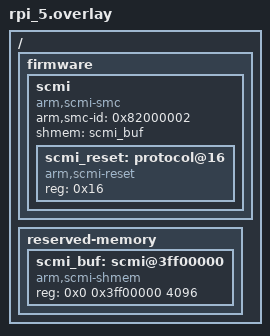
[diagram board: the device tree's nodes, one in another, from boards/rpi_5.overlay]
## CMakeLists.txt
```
# Copyright 2024 EPAM Systems
#
# SPDX-License-Identifier: Apache-2.0

cmake_minimum_required(VERSION 3.20.0)
find_package(Zephyr REQUIRED HINTS $ENV{ZEPHYR_BASE})
project(arm_scmi_shell)

target_sources(app PRIVATE
	src/main.c
	src/shell.c
)

target_sources_ifdef(CONFIG_ARM_SCMI_RESET_HELPERS app PRIVATE
	src/shell_reset.c
)
```

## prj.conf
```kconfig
# Copyright 2024 EPAM Systems
# SPDX-License-Identifier: Apache-2.0

CONFIG_LOG=y
CONFIG_LOG_MODE_MINIMAL=y
CONFIG_PRINTK=y
CONFIG_SHELL=y

CONFIG_ARM_SCMI=y
CONFIG_ARM_SCMI_BASE_EXT_REV=y
```

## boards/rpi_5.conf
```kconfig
# Copyright (c) 2024 EPAM Systems
# SPDX-License-Identifier: Apache-2.0

CONFIG_ARM_SCMI_BASE_AGENT_HELPERS=y
CONFIG_RESET=y
```

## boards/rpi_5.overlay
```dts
/*
 * Copyright (c) 2024 EPAM Systems
 *
 * SPDX-License-Identifier: Apache-2.0
 */

/ {
	firmware {
		scmi {
			compatible = "arm,scmi-smc";
			arm,smc-id = <0x82000002>;
			#address-cells = <1>;
			#size-cells = <0>;
			shmem = <&scmi_buf>;

			scmi_reset: protocol@16 {
				compatible = "arm,scmi-reset";
				reg = <0x16>;
				#reset-cells = <1>;
			};
		};
	};

	reserved-memory {
		#address-cells = <2>;
		#size-cells = <1>;
		ranges;

		scmi_buf: scmi@3ff00000 {
			compatible = "arm,scmi-shmem";
			reg = <0x0 0x3ff00000 4096>;
		};
	};
};
```

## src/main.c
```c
/*
 * Copyright (c) 2024 EPAM Systems
 *
 * SPDX-License-Identifier: Apache-2.0
 *
 * A sample application for demonstrating ARM SCMI Platform interface access using shell commands.
 */

#include <zephyr/kernel.h>

int main(void)
{
	printk("ARM SCMI shell sample\n");
}
```

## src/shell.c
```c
/*
 * System Control and Management Interface (SCMI) Shell interface
 *
 * Copyright (c) 2024 EPAM Systems
 *
 * SPDX-License-Identifier: Apache-2.0
 */

#include <zephyr/kernel.h>
#include <zephyr/drivers/firmware/scmi/protocol.h>
#include <zephyr/drivers/firmware/scmi/base.h>
#include <zephyr/shell/shell.h>

static int scmi_shell_base_revision(const struct shell *sh, size_t argc, char **argv)
{
	struct scmi_revision_info rev;
	int ret;

	ret = scmi_base_get_revision_info(&rev);
	if (ret) {
		shell_error(sh, "base proto get revision failed (%d)", ret);
		return ret;
	}

	shell_print(sh, "ARM SCMI base protocol v%04x.%04x", rev.major_ver, rev.minor_ver);

#if defined(CONFIG_ARM_SCMI_BASE_EXT_REV)
	shell_print(sh, "  vendor\t:%s", rev.vendor_id);
	shell_print(sh, "  subvendor\t:%s", rev.sub_vendor_id);
	shell_print(sh, "  fw version\t:0x%x", rev.impl_ver);
	shell_print(sh, "  protocols\t:%d", rev.num_protocols);
	shell_print(sh, "  num_agents\t:%d", rev.num_agents);
#endif /* CONFIG_ARM_SCMI_BASE_EXT_REV */

	return 0;
}

#if defined(CONFIG_ARM_SCMI_BASE_AGENT_HELPERS)
static int scmi_shell_base_discover_agent(const struct shell *sh, size_t argc, char **argv)
{
	struct scmi_revision_info rev;
	struct scmi_agent_info agent_info;
	uint32_t agent_id = SCMI_BASE_AGENT_ID_OWN;
	int ret;

	if (argc > 2) {
		return -EINVAL;
	}

	if (argc == 2) {
		agent_id = atoi(argv[1]);
	}

	ret = scmi_base_get_revision_info(&rev);
	if (ret) {
		shell_error(sh, "base proto get revision failed (%d)", ret);
		return ret;
	}

	if (agent_id != SCMI_BASE_AGENT_ID_OWN && agent_id >= rev.num_agents) {
		shell_error(sh, "base proto invalid agent id (%u)", agent_id);
		return -EINVAL;
	}

	ret = scmi_base_discover_agent(agent_id, &agent_info);
	if (ret) {
		shell_error(sh, "base proto discover agent failed (%d)", ret);
		return ret;
	}

	shell_print(sh, "  agent id\t:%u", agent_info.agent_id);
	shell_print(sh, "  agent name\t:%s", agent_info.name);
	return 0;
}

static int scmi_shell_base_device_permission(const struct shell *sh, size_t argc, char **argv)
{
	uint32_t agent_id, device_id;
	bool allow;
	int ret;

	if (argc != 4) {
		return -EINVAL;
	}

	agent_id = atoi(argv[1]);
	device_id = atoi(argv[2]);
	allow = !!atoi(argv[3]);

	ret = scmi_base_device_permission(agent_id, device_id, allow);
	if (ret) {
		shell_error(sh, "base proto device permission failed (%d)", ret);
		return ret;
	}

	shell_print(sh, "agent:%u device:%u permission set to %s", agent_id, device_id,
		    allow ? "allow" : "deny");

	return 0;
}

static int scmi_shell_base_reset_agent_cfg(const struct shell *sh, size_t argc, char **argv)
{
	uint32_t agent_id;
	bool reset_perm;
	int ret;

	if (argc != 3) {
		return -EINVAL;
	}

	agent_id = atoi(argv[1]);
	reset_perm = !!atoi(argv[2]);

	ret = scmi_base_reset_agent_cfg(agent_id, reset_perm);
	if (ret) {
		shell_error(sh, "base proto reset agent cfg failed (%d)", ret);
		return ret;
	}

	shell_print(sh, "agent:%u reset cfg reset_perm:%s", agent_id,
		    reset_perm ? "reset" : "none");

	return 0;
}
#endif /* CONFIG_ARM_SCMI_BASE_AGENT_HELPERS */

SHELL_STATIC_SUBCMD_SET_CREATE(sub_scmi_base_cmds,
	SHELL_CMD(revision, NULL,
		  "SCMI Base get revision info\n"
		  "Usage: arm_scmi base revision\n",
		  scmi_shell_base_revision),
#if defined(CONFIG_ARM_SCMI_BASE_AGENT_HELPERS)
	SHELL_CMD_ARG(discover_agent, NULL,
		  "SCMI Base discover an agent\n"
		  "Usage: arm_scmi base discover_agent [agent_id]\n",
		  scmi_shell_base_discover_agent, 1, 2),
	SHELL_CMD_ARG(device_permission, NULL,
		  "SCMI Base set an agent permissions to access device\n"
		  "Usage: arm_scmi base discover_agent <agent_id> <device_id> <allow := 0|1>\n",
		  scmi_shell_base_device_permission, 4, 0),
	SHELL_CMD_ARG(reset_agent_cfg, NULL,
		  "SCMI Base reset an agent configuration\n"
		  "Usage: arm_scmi base reset_agent_cfg <agent_id> <reset_perm := 0|1>\n",
		  scmi_shell_base_reset_agent_cfg, 3, 0),
#endif /* CONFIG_ARM_SCMI_BASE_AGENT_HELPERS */
	SHELL_SUBCMD_SET_END);

SHELL_SUBCMD_ADD((arm_scmi), base, &sub_scmi_base_cmds, "SCMI Base proto commands.",
		 NULL, 1, 0);

SHELL_SUBCMD_SET_CREATE(subcmd_arm_scmi, (arm_scmi));

SHELL_CMD_REGISTER(arm_scmi, &subcmd_arm_scmi, "ARM SCMI commands", NULL);
```

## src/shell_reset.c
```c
/*
 * SCMI Reset domain management protocol Shell interface
 *
 * Copyright (c) 2024 EPAM Systems
 *
 * SPDX-License-Identifier: Apache-2.0
 */

#include <zephyr/drivers/firmware/scmi/reset.h>
#include <zephyr/drivers/reset.h>
#include <zephyr/shell/shell.h>

#if defined(CONFIG_DT_HAS_ARM_SCMI_RESET_ENABLED)
static const struct device *reset_dev = DEVICE_DT_GET_ANY(arm_scmi_reset);
#else
BUILD_ASSERT(1, "unsupported scmi reset interface");
#endif

static int scmi_shell_reset_revision(const struct shell *sh, size_t argc, char **argv)
{
	struct scmi_protocol_version ver;
	struct scmi_protocol *proto;
	uint16_t num_domains;
	int ret;

	proto = reset_dev->data;

	ret = scmi_core_get_version(proto, &ver);
	if (ret) {
		shell_error(sh, "reset get version failed (%d)", ret);
		return ret;
	}

	ret = scmi_reset_get_attr(proto, &num_domains);
	if (ret) {
		shell_error(sh, "reset get attributes failed (%d)", ret);
		return ret;
	}

	shell_print(sh, "ARM SCMI Reset protocol version 0x%04x.%04x num_domains:%u", ver.major,
		    ver.minor, num_domains);

	return 0;
}

static int scmi_shell_reset_dom_list(const struct shell *sh, size_t argc, char **argv)
{
	struct scmi_reset_domain_attr dom_attr;
	struct scmi_protocol *proto;
	uint16_t num_domains;
	uint16_t i;
	int ret;

	proto = reset_dev->data;

	ret = scmi_reset_get_attr(proto, &num_domains);
	if (ret) {
		shell_error(sh, "reset get attributes failed (%d)", ret);
		return ret;
	}

	shell_print(sh, "domain_id,name,latency,attributes");

	for (i = 0; i < num_domains; i++) {
		ret = scmi_reset_domain_get_attr(proto, i, &dom_attr);
		if (ret) {
			shell_error(sh, "reset domain:%u get attributes failed (%d)", ret, i);
			return ret;
		}

		shell_print(sh, "%u,%s,0x%08x,async=%s,notify=%s,latency=%s", i, dom_attr.name,
			    dom_attr.latency, dom_attr.is_async_sup ? "yes" : "no",
			    dom_attr.is_notifications_sup ? "yes" : "no",
			    dom_attr.is_latency_valid ? "valid" : "invalid");
	}

	return 0;
}

static int scmi_shell_reset_info(const struct shell *sh, size_t argc, char **argv)
{
	struct scmi_reset_domain_attr dom_attr;
	struct scmi_protocol *proto;
	uint16_t num_domains;
	uint32_t domain_id;
	int ret;

	proto = reset_dev->data;

	ret = scmi_reset_get_attr(proto, &num_domains);
	if (ret) {
		shell_error(sh, "reset get attributes failed (%d)", ret);
		return ret;
	}

	domain_id = atoi(argv[1]);
	if (domain_id >= num_domains) {
		shell_error(sh, "invalid reset domain index %s\n", argv[1]);
		return -ENOENT;
	}

	ret = scmi_reset_domain_get_attr(proto, domain_id, &dom_attr);
	if (ret) {
		shell_error(sh, "reset domain get attributes failed (%d)", ret);
		return ret;
	}

	shell_print(sh, "ARM SCMI reset domain: %u", domain_id);
	shell_print(sh, " name\t\t: %s", dom_attr.name);
	if (dom_attr.is_latency_valid) {
		shell_print(sh, " latency\t: %u", dom_attr.latency);
	} else {
		shell_print(sh, " latency\t: invalid");
	}
	shell_print(sh, " async\t\t: %s", dom_attr.is_async_sup ? "supported" : "not supported");
	shell_print(sh, " notifications\t\t: %s",
		    dom_attr.is_notifications_sup ? "supported" : "not supported");

	return 0;
}

static int scmi_shell_reset_assert(const struct shell *sh, size_t argc, char **argv)
{
	uint32_t domain_id;
	int ret;

	domain_id = atoi(argv[1]);

	ret = reset_line_assert(reset_dev, domain_id);
	if (ret) {
		shell_error(sh, "reset domain:%u assert failed (%d)", domain_id, ret);
	} else {
		shell_info(sh, "reset domain:%u assert done", domain_id);
	}

	return ret;
}

static int scmi_shell_reset_deassert(const struct shell *sh, size_t argc, char **argv)
{
	uint32_t domain_id;
	int ret;

	domain_id = atoi(argv[1]);

	ret = reset_line_deassert(reset_dev, domain_id);
	if (ret) {
		shell_error(sh, "reset domain:%u deassert failed (%d)", domain_id, ret);
	} else {
		shell_info(sh, "reset domain:%u deassert done", domain_id);
	}

	return ret;
}

static int scmi_shell_reset_toggle(const struct shell *sh, size_t argc, char **argv)
{
	uint32_t domain_id;
	int ret;

	domain_id = atoi(argv[1]);

	ret = reset_line_toggle(reset_dev, domain_id);
	if (ret) {
		shell_error(sh, "reset domain:%u toggle failed (%d)", domain_id, ret);
	} else {
		shell_info(sh, "reset domain:%u toggle done", domain_id);
	}

	return ret;
}

SHELL_STATIC_SUBCMD_SET_CREATE(sub_scmi_reset_cmds,
	SHELL_CMD_ARG(revision, NULL,
		      "SCMI Reset proto show revision information\n"
		      "Usage: arm_scmi reset revision\n",
		      scmi_shell_reset_revision, 1, 0),
	SHELL_CMD_ARG(list, NULL,
		      "SCMI Reset domains list\n"
		      "Usage: arm_scmi reset list\n",
		      scmi_shell_reset_dom_list, 1, 0),
	SHELL_CMD_ARG(info, NULL,
		      "SCMI Reset domain show info\n"
		      "Usage: arm_scmi reset info <domain_id>\n",
		      scmi_shell_reset_info, 2, 0),
	SHELL_CMD_ARG(assert, NULL,
		      "SCMI Reset domain assert\n"
		      "Usage: arm_scmi reset assert <domain_id>\n",
		      scmi_shell_reset_assert, 2, 0),
	SHELL_CMD_ARG(deassert, NULL,
		      "SCMI Reset domain de-assert\n"
		      "Usage: arm_scmi reset deassert <domain_id>\n",
		      scmi_shell_reset_deassert, 2, 0),
	SHELL_CMD_ARG(autoreset, NULL,
		      "SCMI Reset domain Autonomous reset\n"
		      "Usage: arm_scmi reset autoreset <domain_id>\n",
		      scmi_shell_reset_toggle, 2, 0),
	SHELL_SUBCMD_SET_END);

SHELL_SUBCMD_ADD((arm_scmi), reset, &sub_scmi_reset_cmds,
		 "SCMI Reset proto commands.",
		 NULL, 1, 1);
```
